# STM32L552 register map
File version: 1.5
CPU: CM33 r0p1, little endian, MPU, FPU, 3 interrupt priority bits
Registers are 32-bit, read-write, reset 0x0 unless marked. A register's access mark holds for its fields unless they carry their own. Offsets are from the block's base; [hi:lo] are bit positions; 'fields as' and 'values as' point back to an identical list.

## TIM15 — General purpose timers
Base 0x40014000
Same registers: SEC_TIM15 0x50014000
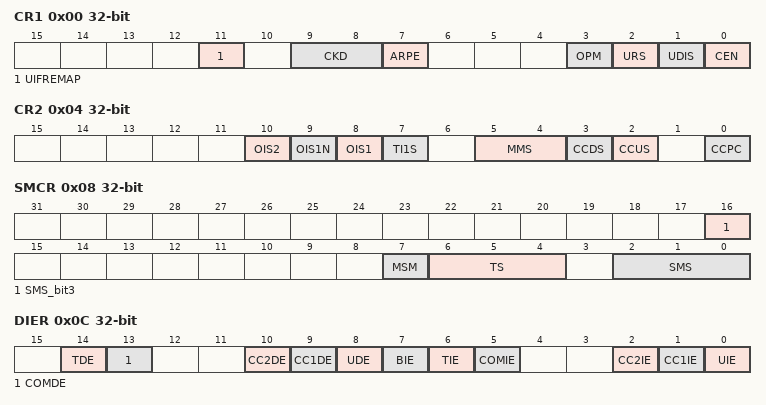
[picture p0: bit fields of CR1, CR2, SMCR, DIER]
0x00 CR1 — control register 1
  [11] UIFREMAP — UIF status bit remapping
  [9:8] CKD — Clock division
  [7] ARPE — Auto-reload preload enable
  [3] OPM — One-pulse mode
  [2] URS — Update request source
  [1] UDIS — Update disable
  [0] CEN — Counter enable
0x04 CR2 — control register 2
  [10] OIS2 — Output idle state 2 (OC2 output)
  [9] OIS1N — Output Idle state 1
  [8] OIS1 — Output Idle state 1
  [7] TI1S — TI1 selection
  [5:4] MMS — Master mode selection
  [3] CCDS — Capture/compare DMA selection
  [2] CCUS — Capture/compare control update selection
  [0] CCPC — Capture/compare preloaded control
0x08 SMCR — TIM15 slave mode control register
  [16] SMS_bit3 — Slave mode selection - bit 3
  [7] MSM — Master/slave mode
  [6:4] TS — Trigger selection
  [2:0] SMS — Slave mode selection
0x0C DIER — DMA/Interrupt enable register
  [14] TDE — Trigger DMA request enable
  [13] COMDE — COM DMA request enable
  [10] CC2DE — Capture/Compare 2 DMA request enable
  [9] CC1DE — Capture/Compare 1 DMA request enable
  [8] UDE — Update DMA request enable
  [7] BIE — Break interrupt enable
  [6] TIE — Trigger interrupt enable
  [5] COMIE — COM interrupt enable
  [2] CC2IE — Capture/Compare 2 interrupt enable
  [1] CC1IE — Capture/Compare 1 interrupt enable
  [0] UIE — Update interrupt enable
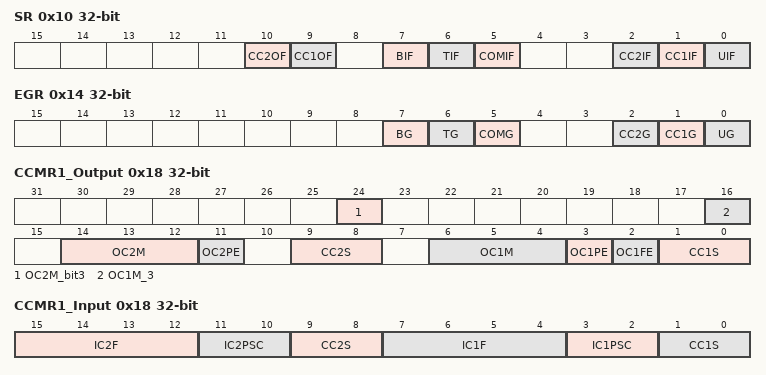
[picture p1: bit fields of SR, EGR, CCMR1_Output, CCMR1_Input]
0x10 SR — status register
  [10] CC2OF — Capture/Compare 2 overcapture flag
  [9] CC1OF — Capture/Compare 1 overcapture flag
  [7] BIF — Break interrupt flag
  [6] TIF — Trigger interrupt flag
  [5] COMIF — COM interrupt flag
  [2] CC2IF — Capture/Compare 2 interrupt flag
  [1] CC1IF — Capture/compare 1 interrupt flag
  [0] UIF — Update interrupt flag
0x14 EGR wo — event generation register
  [7] BG — Break generation
  [6] TG — Trigger generation
  [5] COMG — Capture/Compare control update generation
  [2] CC2G — Capture/Compare 2 generation
  [1] CC1G — Capture/compare 1 generation
  [0] UG — Update generation
0x18 CCMR1_Output — capture/compare mode register (output mode)
  [24] OC2M_bit3 — Output Compare 2 mode - bit 3
  [16] OC1M_3 — Output Compare 1 mode
    0=Normal output compare mode (modes 0-7); 1=Extended output compare mode (modes 7-15)
  [14:12] OC2M — Output Compare 2 mode
    0=Frozen (The comparison between the output compare register TIMx_CCRy and the counter TIMx_CNT has no effect on the outputs / OpmMode1: Retriggerable OPM mode 1 - In up-counting mode, the channel is active until a trigger event is detected (on TRGI signal). In down-counting mode, the channel is inactive); 1=ActiveOnMatch (Set channel to active level on match. OCyREF signal is forced high when the counter matches the capture/compare register / OpmMode2: Inversely to OpmMode1); 2=InactiveOnMatch (Set channel to inactive level on match. OCyREF signal is forced low when the counter matches the capture/compare register / Reserved); 3=Toggle (OCyREF toggles when TIMx_CNT=TIMx_CCRy / Reserved); 4=ForceInactive (OCyREF is forced low / CombinedPwmMode1: OCyREF has the same behavior as in PWM mode 1. OCyREFC is the logical OR between OC1REF and OC2REF); 5=ForceActive (OCyREF is forced high / CombinedPwmMode2: OCyREF has the same behavior as in PWM mode 2. OCyREFC is the logical AND between OC1REF and OC2REF); 6=PwmMode1 (In upcounting, channel is active as long as TIMx_CNT<TIMx_CCRy else inactive. In downcounting, channel is inactive as long as TIMx_CNT>TIMx_CCRy else active / Reserved); 7=PwmMode2 (Inversely to PwmMode1 / Reserved)
  [11] OC2PE — Output Compare 2 preload enable
  [9:8] CC2S — Capture/Compare 2 selection
  [6:4] OC1M — Output Compare 1 mode
    values as OC2M
  [3] OC1PE — Output Compare 1 preload enable
  [2] OC1FE — Output Compare 1 fast enable
  [1:0] CC1S — Capture/Compare 1 selection
0x18 CCMR1_Input (alternate view of CCMR1_Output) — capture/compare mode register 1 (input mode)
  [15:12] IC2F — Input capture 2 filter
  [11:10] IC2PSC — Input capture 2 prescaler
  [9:8] CC2S — Capture/Compare 2 selection
  [7:4] IC1F — Input capture 1 filter
  [3:2] IC1PSC — Input capture 1 prescaler
  [1:0] CC1S — Capture/Compare 1 selection
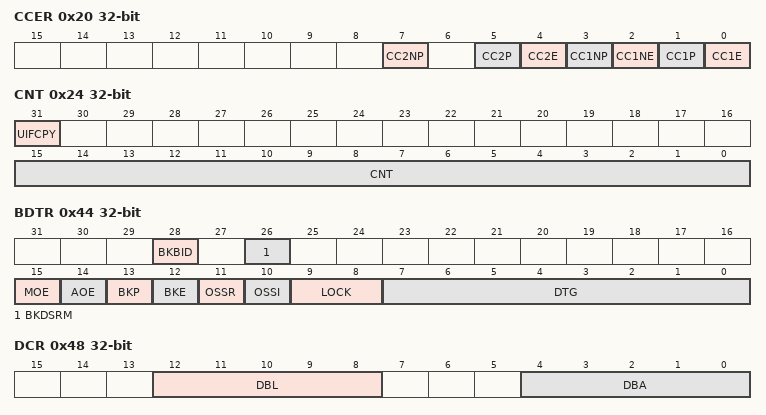
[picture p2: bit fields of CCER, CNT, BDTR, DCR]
0x20 CCER — capture/compare enable register
  [7] CC2NP — Capture/Compare 2 complementary output polarity
  [5] CC2P — Capture/Compare 2 output polarity
  [4] CC2E — Capture/Compare 2 output enable
  [3] CC1NP — Capture/Compare 1 output Polarity
  [2] CC1NE — Capture/Compare 1 complementary output enable
  [1] CC1P — Capture/Compare 1 output Polarity
  [0] CC1E — Capture/Compare 1 output enable
0x24 CNT access per field — counter
  [31] UIFCPY ro — UIF Copy
  [15:0] CNT rw — counter value
0x28 PSC — prescaler
  [15:0] PSC — Prescaler value
0x28 CCR2 (alternate view of PSC) — TIM15 capture/compare register 2
  [15:0] CCR2 — Capture/Compare 2 value
0x2C ARR — auto-reload register
  [15:0] ARR — Auto-reload value
0x30 RCR — repetition counter register
  [7:0] REP — Repetition counter value
0x34 CCR1 — capture/compare register 1
  [15:0] CCR1 — Capture/Compare 1 value
0x44 BDTR — break and dead-time register
  [28] BKBID — Break Bidirectional
  [26] BKDSRM — Break Disarm
  [15] MOE — Main output enable
  [14] AOE — Automatic output enable
  [13] BKP — Break polarity
  [12] BKE — Break enable
  [11] OSSR — Off-state selection for Run mode
  [10] OSSI — Off-state selection for Idle mode
  [9:8] LOCK — Lock configuration
  [7:0] DTG — Dead-time generator setup
0x48 DCR — DMA control register
  [12:8] DBL — DMA burst length
  [4:0] DBA — DMA base address
0x4C DMAR — DMA address for full transfer
  [15:0] DMAB — DMA register for burst accesses
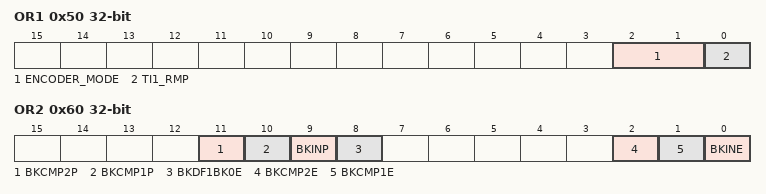
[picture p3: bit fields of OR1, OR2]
0x50 OR1 — TIM15 option register 1
  [2:1] ENCODER_MODE
  [0] TI1_RMP — Input capture 1 remap
0x60 OR2 — TIM15 option register 2
  [11] BKCMP2P — BRK COMP2 input polarity
  [10] BKCMP1P — BRK COMP1 input polarity
  [9] BKINP — BRK BKIN input polarity
  [8] BKDF1BK0E — BRK dfsdm1_break[0] enable
  [2] BKCMP2E — BRK COMP2 enable
  [1] BKCMP1E — BRK COMP1 enable
  [0] BKINE — BRK BKIN input enable
